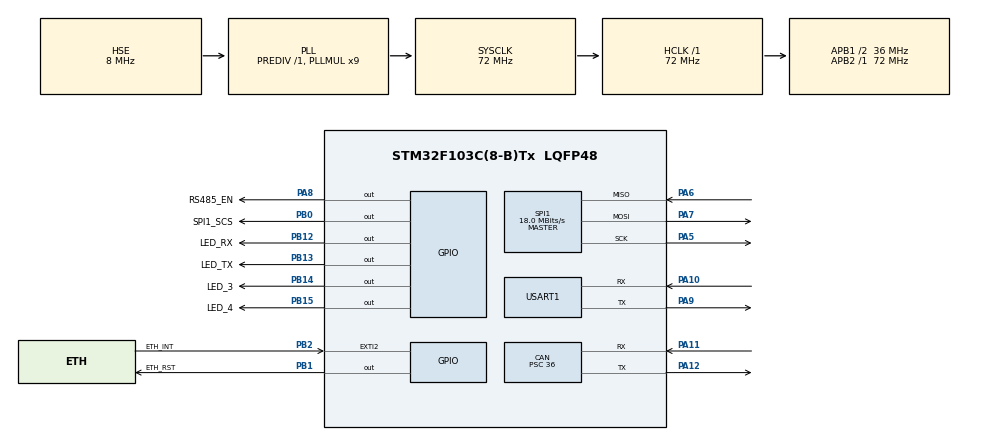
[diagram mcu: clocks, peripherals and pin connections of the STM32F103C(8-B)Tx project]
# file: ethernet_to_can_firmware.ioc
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CAN.ABOM=ENABLE
CAN.AWUM=DISABLE
CAN.BS1=CAN_BS1_2TQ
CAN.CalculateBaudRate=250000
CAN.CalculateTimeBit=4000
CAN.CalculateTimeQuantum=1000.0
CAN.Mode=CAN_MODE_NORMAL
CAN.NART=DISABLE
CAN.Prescaler=36
CAN.SJW=CAN_SJW_1TQ
Dma.Request0=USART1_RX
Dma.Request1=USART1_TX
Dma.USART1_RX.0.Direction=DMA_PERIPH_TO_MEMORY
Dma.USART1_RX.0.Instance=DMA1_Channel5
Dma.USART1_RX.0.MemDataAlignment=DMA_MDATAALIGN_BYTE
Dma.USART1_RX.0.MemInc=DMA_MINC_ENABLE
Dma.USART1_RX.0.Mode=DMA_CIRCULAR
Dma.USART1_RX.0.PeriphDataAlignment=DMA_PDATAALIGN_BYTE
Dma.USART1_RX.0.PeriphInc=DMA_PINC_DISABLE
Dma.USART1_RX.0.Priority=DMA_PRIORITY_LOW
Dma.USART1_TX.1.Direction=DMA_MEMORY_TO_PERIPH
Dma.USART1_TX.1.Instance=DMA1_Channel4
Dma.USART1_TX.1.MemDataAlignment=DMA_MDATAALIGN_BYTE
Dma.USART1_TX.1.MemInc=DMA_MINC_ENABLE
Dma.USART1_TX.1.Mode=DMA_NORMAL
Dma.USART1_TX.1.PeriphDataAlignment=DMA_PDATAALIGN_BYTE
Dma.USART1_TX.1.PeriphInc=DMA_PINC_DISABLE
Dma.USART1_TX.1.Priority=DMA_PRIORITY_LOW
FREERTOS.Tasks01=ethernetHandler,24,256,StartEthernetHandlerTask,Default,NULL,Dynamic,NULL,NULL
FREERTOS.configUSE_NEWLIB_REENTRANT=1
FREERTOS.configUSE_PREEMPTION=0
Mcu.Family=STM32F1
Mcu.Name=STM32F103C(8-B)Tx
Mcu.Package=LQFP48
NVIC.DMA1_Channel4_IRQn=true\:5\:0\:false\:false\:true\:true\:false\:true\:true
NVIC.DMA1_Channel5_IRQn=true\:5\:0\:false\:false\:true\:true\:false\:true\:true
NVIC.EXTI2_IRQn=true\:5\:0\:true\:false\:true\:true\:true\:true\:true
NVIC.PriorityGroup=NVIC_PRIORITYGROUP_4
NVIC.TIM4_IRQn=true\:0\:0\:true\:false\:true\:false\:false\:true\:true
NVIC.TimeBase=TIM4_IRQn
NVIC.TimeBaseIP=TIM4
NVIC.USART1_IRQn=true\:5\:0\:true\:false\:true\:true\:true\:true\:true
NVIC.USB_LP_CAN1_RX0_IRQn=true\:5\:0\:true\:false\:true\:true\:true\:true\:true
PA10.Mode=Asynchronous
PA10.Signal=USART1_RX
PA11.GPIO_PuPd=GPIO_NOPULL
PA11.Mode=CAN_Activate
PA11.Signal=CAN_RX
PA12.Mode=CAN_Activate
PA12.Signal=CAN_TX
PA13.Mode=Serial_Wire
PA13.Signal=SYS_JTMS-SWDIO
PA14.Mode=Serial_Wire
PA14.Signal=SYS_JTCK-SWCLK
PA5.Mode=Full_Duplex_Master
PA5.Signal=SPI1_SCK
PA6.Mode=Full_Duplex_Master
PA6.Signal=SPI1_MISO
PA7.Mode=Full_Duplex_Master
PA7.Signal=SPI1_MOSI
PA8.GPIO_Label=RS485_EN
PA8.Signal=GPIO_Output
PA9.Mode=Asynchronous
PA9.Signal=USART1_TX
PB0.GPIO_Label=SPI1_SCS
PB0.Signal=GPIO_Output
PB1.GPIO_Label=ETH_RST
PB1.Signal=GPIO_Output
PB12.GPIO_Label=LED_RX
PB12.Signal=GPIO_Output
PB13.GPIO_Label=LED_TX
PB13.Signal=GPIO_Output
PB14.GPIO_Label=LED_3
PB14.Signal=GPIO_Output
PB15.GPIO_Label=LED_4
PB15.Signal=GPIO_Output
PB2.GPIO_Label=ETH_INT
PB2.GPIO_ModeDefaultEXTI=GPIO_MODE_IT_FALLING
PB2.GPIO_PuPd=GPIO_NOPULL
PB2.Signal=GPXTI2
PD0-OSC_IN.Mode=HSE-External-Oscillator
PD0-OSC_IN.Signal=RCC_OSC_IN
PD1-OSC_OUT.Mode=HSE-External-Oscillator
PD1-OSC_OUT.Signal=RCC_OSC_OUT
ProjectManager.HeapSize=0x200
ProjectManager.StackSize=0x400
ProjectManager.TargetToolchain=CMake
RCC.AHBFreq_Value=72000000
RCC.APB1CLKDivider=RCC_HCLK_DIV2
RCC.APB1Freq_Value=36000000
RCC.APB1TimFreq_Value=72000000
RCC.APB2Freq_Value=72000000
RCC.APB2TimFreq_Value=72000000
RCC.HCLKFreq_Value=72000000
RCC.PLLMUL=RCC_PLL_MUL9
RCC.PLLSourceVirtual=RCC_PLLSOURCE_HSE
RCC.RCC_MCOSource=RCC_MCO1SOURCE_HSE
RCC.SYSCLKFreq_VALUE=72000000
RCC.SYSCLKSource=RCC_SYSCLKSOURCE_PLLCLK
RCC.USBFreq_Value=72000000
SPI1.BaudRatePrescaler=SPI_BAUDRATEPRESCALER_4
SPI1.CRCCalculation=SPI_CRCCALCULATION_DISABLE
SPI1.CalculateBaudRate=18.0 MBits/s
SPI1.DataSize=SPI_DATASIZE_8BIT
SPI1.Direction=SPI_DIRECTION_2LINES
SPI1.Mode=SPI_MODE_MASTER
SPI1.VirtualNSS=VM_NSSHARD
SPI1.VirtualType=VM_MASTER
USART1.VirtualMode=VM_ASYNC
VP_FREERTOS_VS_CMSIS_V2.Mode=CMSIS_V2
VP_SYS_VS_tim4.Mode=TIM4
board=custom

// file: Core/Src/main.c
/* USER CODE BEGIN Header */
/**
  ******************************************************************************
  * @file           : main.c
  * @brief          : Main program body
  ******************************************************************************
  * @attention
  *
  * Copyright (c) 2022 STMicroelectronics.
  * All rights reserved.
  *
  * This software is licensed under terms that can be found in the LICENSE file
  * in the root directory of this software component.
  * If no LICENSE file comes with this software, it is provided AS-IS.
  *
  ******************************************************************************
  */
/* USER CODE END Header */
#include "main.h"
#include "cmsis_os.h"
#include "can.h"
#include "dma.h"
#include "spi.h"
#include "usart.h"
#include "gpio.h"

void SystemClock_Config(void);
void MX_FREERTOS_Init(void);

int main(void)
{

  /* MCU Configuration--------------------------------------------------------*/

  /* Reset of all peripherals, Initializes the Flash interface and the Systick. */
  HAL_Init();

  /* Configure the system clock */
  SystemClock_Config();

  /* Initialize all configured peripherals */
  MX_GPIO_Init();
  MX_DMA_Init();
  MX_SPI1_Init();
  MX_USART1_UART_Init();
  MX_CAN_Init();

  /* Init scheduler */
  osKernelInitialize();  /* Call init function for freertos objects (in cmsis_os2.c) */
  MX_FREERTOS_Init();

  /* Start scheduler */
  osKernelStart();

  /* We should never get here as control is now taken by the scheduler */

  /* Infinite loop */
  while (1)
  {

  }
}

void SystemClock_Config(void)
{
  RCC_OscInitTypeDef RCC_OscInitStruct = {0};
  RCC_ClkInitTypeDef RCC_ClkInitStruct = {0};

  /** Initializes the RCC Oscillators according to the specified parameters
  * in the RCC_OscInitTypeDef structure.
  */
  RCC_OscInitStruct.OscillatorType = RCC_OSCILLATORTYPE_HSE;
  RCC_OscInitStruct.HSEState = RCC_HSE_ON;
  RCC_OscInitStruct.HSEPredivValue = RCC_HSE_PREDIV_DIV1;
  RCC_OscInitStruct.HSIState = RCC_HSI_ON;
  RCC_OscInitStruct.PLL.PLLState = RCC_PLL_ON;
  RCC_OscInitStruct.PLL.PLLSource = RCC_PLLSOURCE_HSE;
  RCC_OscInitStruct.PLL.PLLMUL = RCC_PLL_MUL9;
  if (HAL_RCC_OscConfig(&RCC_OscInitStruct) != HAL_OK)
  {
    Error_Handler();
  }

  /** Initializes the CPU, AHB and APB buses clocks
  */
  RCC_ClkInitStruct.ClockType = RCC_CLOCKTYPE_HCLK|RCC_CLOCKTYPE_SYSCLK
                              |RCC_CLOCKTYPE_PCLK1|RCC_CLOCKTYPE_PCLK2;
  RCC_ClkInitStruct.SYSCLKSource = RCC_SYSCLKSOURCE_PLLCLK;
  RCC_ClkInitStruct.AHBCLKDivider = RCC_SYSCLK_DIV1;
  RCC_ClkInitStruct.APB1CLKDivider = RCC_HCLK_DIV2;
  RCC_ClkInitStruct.APB2CLKDivider = RCC_HCLK_DIV1;

  if (HAL_RCC_ClockConfig(&RCC_ClkInitStruct, FLASH_LATENCY_2) != HAL_OK)
  {
    Error_Handler();
  }
}

void HAL_TIM_PeriodElapsedCallback(TIM_HandleTypeDef *htim)
{
  if (htim->Instance == TIM4)
  {
    HAL_IncTick();
  }
}

void Error_Handler(void)
{
  __disable_irq();
  while (1)
  {
  }
}

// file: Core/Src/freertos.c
/* USER CODE BEGIN Header */
/**
  ******************************************************************************
  * File Name          : freertos.c
  * Description        : Code for freertos applications
  ******************************************************************************
  * @attention
  *
  * Copyright (c) 2022 STMicroelectronics.
  * All rights reserved.
  *
  * This software is licensed under terms that can be found in the LICENSE file
  * in the root directory of this software component.
  * If no LICENSE file comes with this software, it is provided AS-IS.
  *
  ******************************************************************************
  */
/* USER CODE END Header */

#include "FreeRTOS.h"
#include "task.h"
#include "main.h"
#include "cmsis_os.h"

/* USER CODE BEGIN Includes */
#include "bridge.h"

/* USER CODE END Includes */

/* Definitions for ethernetHandler */
osThreadId_t ethernetHandlerHandle;
const osThreadAttr_t ethernetHandler_attributes = {
  .name = "ethernetHandler",
  .stack_size = 256 * 4,
  .priority = (osPriority_t) osPriorityNormal,
};

void StartEthernetHandlerTask(void *argument);

void MX_FREERTOS_Init(void); /* (MISRA C 2004 rule 8.1) */

void MX_FREERTOS_Init(void) {

  /* Create the thread(s) */
  /* creation of ethernetHandler */
  ethernetHandlerHandle = osThreadNew(StartEthernetHandlerTask, NULL, &ethernetHandler_attributes);

  /* USER CODE BEGIN RTOS_THREADS */
  if (ethernetHandlerHandle == NULL) Error_Handler();
  /* add threads, ... */
  /* USER CODE END RTOS_THREADS */

}

void StartEthernetHandlerTask(void *argument)
{
  /* USER CODE BEGIN StartEthernetHandlerTask */
  Bridge_Init();
  for (;;)
  {
    Bridge_Step();
    if ((bridge_diagnostics.task_iterations % 1000U) == 0U)
      bridge_diagnostics.stack_free_bytes = uxTaskGetStackHighWaterMark(NULL) * sizeof(StackType_t);
    osDelay(1);
  }
  /* USER CODE END StartEthernetHandlerTask */
}
